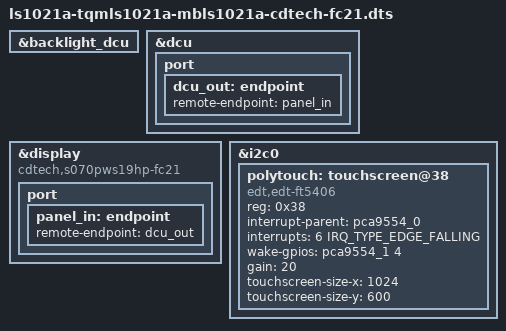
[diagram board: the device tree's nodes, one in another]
// SPDX-License-Identifier: (GPL-2.0-or-later OR X11)
/*
 * Copyright 2018-2023 TQ-Systems GmbH <linux@ew.tq-group.com>,
 * D-82229 Seefeld, Germany.
 * Author: Alexander Stein

 */

/dts-v1/;
/plugin/;

#include <dt-bindings/gpio/gpio.h>
#include <dt-bindings/interrupt-controller/irq.h>

&backlight_dcu {
	status = "okay";
};

&dcu {
	status = "okay";

	port {
		dcu_out: endpoint {
			remote-endpoint = <&panel_in>;
		};
	};
};

&display {
	compatible = "cdtech,s070pws19hp-fc21";
	status = "okay";

	port {
		panel_in: endpoint {
			remote-endpoint = <&dcu_out>;
		};
	};
};

&i2c0 {
	#address-cells = <1>;
	#size-cells = <0>;

	polytouch: touchscreen@38 {
		compatible = "edt,edt-ft5406";
		reg = <0x38>;
		interrupt-parent = <&pca9554_0>;
		interrupts = <6 IRQ_TYPE_EDGE_FALLING>;
		/* LCD_PWR_EN -> TSC_WAKE */
		wake-gpios = <&pca9554_1 4 GPIO_ACTIVE_HIGH>;
		gain = <20>;
		touchscreen-size-x = <1024>;
		touchscreen-size-y = <600>;
	};
};
